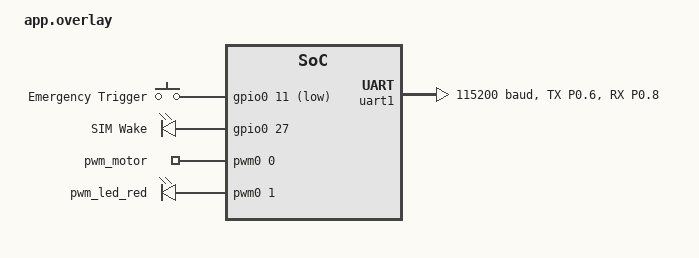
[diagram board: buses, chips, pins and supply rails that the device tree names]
/ {
    aliases {
        sw0 = &button0;
        sim-uart = &uart1;
        haptic = &pwm_motor;
        led-red = &pwm_led_red;
        sim-pwr = &sim_pwr_pin;
    };

    buttons {
        compatible = "gpio-keys";
        button0: button_0 {
            gpios = <&gpio0 11 (GPIO_PULL_UP | GPIO_ACTIVE_LOW)>;
            label = "Emergency Trigger";
        };
    };

    control_pins {
        compatible = "gpio-leds";
        sim_pwr_pin: sim_pwr_key {
            gpios = <&gpio0 27 GPIO_ACTIVE_HIGH>;
            label = "SIM Wake";
        };
    };

    pwmleds {
        compatible = "pwm-leds";
        pwm_motor: pwm_motor {
            pwms = <&pwm0 0 PWM_MSEC(20) PWM_POLARITY_NORMAL>;
        };
        pwm_led_red: pwm_led_red {
            pwms = <&pwm0 1 PWM_MSEC(20) PWM_POLARITY_NORMAL>;
        };
    };
};

&uart1 {
    status = "okay";
    current-speed = <115200>;
    pinctrl-0 = <&uart1_default>;
    pinctrl-names = "default";
};

&pinctrl {
    uart1_default: uart1_default {
        group1 {
            psels = <NRF_PSEL(UART_TX, 0, 6)>,
                    <NRF_PSEL(UART_RX, 0, 8)>;
        };
    };
};
